# D1H register map
Vendor: Allwinner; File version: 1.0
Registers are 32-bit, read-write, reset 0x0 unless marked. A register's access mark holds for its fields unless they carry their own. Offsets are from the block's base; [hi:lo] are bit positions; {n}, {i} and the like mark numbered series.

## CIR_TX — Counsumer Infrared Transmitter
Base 0x02003000
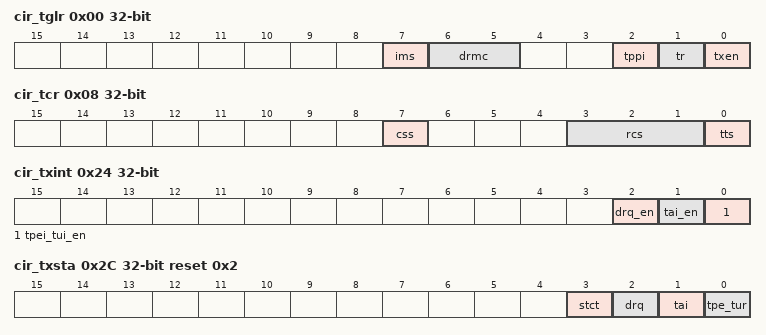
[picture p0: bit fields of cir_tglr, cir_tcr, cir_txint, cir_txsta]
0x00 cir_tglr — CIR Transmit Global Register
  [7] ims — Internal Modulation Select
    0=NOT_MODULATED (The transmitting signal is not modulated); 1=MODULATED (The transmitting signal is modulated internally)
  [6:5] drmc — Duty ratio of modulated carrier is high level/low level.
    0=EQUAL (Low level is equal to high level); 1=DOUBLE (Low level is the double of high level); 2=TRIPLE (Low level is the triple of high level)
  [2] tppi — Transmit Pulse Polarity Invert
    0=NOT_INVERT (Not invert transmit pulse); 1=INVERT (Invert transmit pulse)
  [1] tr — Transmit Reset . When this bit is set, the transmitting is reset. The FIFO will be flushed, the TIC filed and the CSS field will be cleared during Transmit Reset. This field will automatically be cleared when the Transmit Reset is finished, and the CIR transmitter will state Idle.
  [0] txen — Transmit Block Enable
    0=DISABLE (Disable the CIR Transmitter); 1=ENABLE (Enable the CIR Transmitter)
0x04 cir_tmcr reset 0x9E — CIR Transmit Modulation Control Register
  [7:0] rfmc — Reference Frequency of modulated carrier. . Reference Frequency of modulated carrier based on a division of a fixed functional clock (FCLK). The range of the modulated carrier is usually 30 kHz to 60 kHz. Most consumer electronics is 38 kHz. . The default modulated carrier is 38 kHz when FCLK is 12 MHz. . RFMC= FCLK/((N+1)*(DRMC+2)).
0x08 cir_tcr — CIR Transmit Control Register
  [7] css — Cyclical Pulse Start/Stop Control
    0=STOP (Stop when cleared to '0'. From start to stop, all data in FIFO must be transmitted.); 1=START (Start. Start to transmit when it is set to '1'.)
  [3:1] rcs — Reference Clock Select for CIR Transmit . The data in TX_FIFO is used to describe the pulse in Run-Length Code. The basic unit of pulse width is Reference Clock.
    0=IR_CLK (CIR Transmit reference clock is ir_clk); 1=IR_CLK_2 (CIR Transmit reference clock is ir_clk/2); 2=IR_CLK_4 (CIR Transmit reference clock is ir_clk/4); 3=IR_CLK_8 (CIR Transmit reference clock is ir_clk/8); 4=IR_CLK_64 (CIR Transmit reference clock is ir_clk/64); 5=IR_CLK_128 (CIR Transmit reference clock is ir_clk/128); 6=IR_CLK_256 (CIR Transmit reference clock is ir_clk/256); 7=IR_CLK_512 (CIR Transmit reference clock is ir_clk/512)
  [0] tts — Type of the transmission signal
    0=NON_CYCLICAL (The transmitting wave is a single non-cyclical pulse.); 1=CYCLICAL (The transmitting wave is a cyclical short-pulse.)
0x0C cir_idc_h — CIR Transmit Idle Duration Threshold High Bit Register
  [3:0] idc_h — Idle Duration Counter Threshold (High 4 bits) . Idle Duration = 128*IDC*Ts (IDC = 0-4095) . It is used in cyclical transmission mode. When all the data in FIFO is transmitted, the signals can be transmitted after a specific time.
0x10 cir_idc_l — CIR Transmit Idle Duration Threshold Low Bit Register
  [7:0] idc_l — Idle Duration Counter Threshold (Low 8 bits) . Idle Duration = 128*IDC*Ts (IDC = 0-4095) . It is used in cyclical transmission mode. When all the data in FIFO is transmitted, the signals can be transmitted after a specific time.
0x14 cir_ticr_h — CIR Transmit Idle Counter High Bit Register
  [7:0] tic_h ro — Transmit Idle Counter_H (High 8 bits) . It is used to count the idle duration of CIR transmitter by software. . Count in 128*Ts (Sample Duration, 1/Fs) when the transmitter is idle, and it should be reset when the transmitter is active. . When this counter reaches the maximum value (0xFFFF), it will stop automatically, and should not be cleared to zero.
0x18 cir_ticr_l — CIR Transmit Idle Counter Low Bit Register
  [7:0] tic_l ro — Transmit Idle Counter_L (Low 8 bits) . It is used to count the idle duration of CIR transmitter by software. . Count in 128*Ts (Sample Duration, 1/Fs) when the transmitter is idle, and it should be reset when the transmitter is active. . When this counter reaches the maximum value (0xFFFF), it will stop automatically, and should not be cleared to zero.
0x20 cir_tel — CIR TX FIFO Empty Level Register
  [7:0] tel — TX FIFO empty Level for DRQ and IRQ. . TRIGGER_LEVEL = TEL + 1
0x24 cir_txint — CIR Transmit Interrupt Control Register
  [all] fields
    0=DISABLE; 1=ENABLE
  [2] drq_en — TX FIFO DMA Enable . When it is set to '1', the TX FIFO DRQ is asserted if the number of the transmitting data in the FIFO is less than the RAL. The DRQ is de-asserted when the condition fails.
  [1] tai_en — TX FIFO Available Interrupt Enable
  [0] tpei_tui_en — Transmit Packet End Interrupt Enable for Cyclical Pulse / Transmitter FIFO Underrun Interrupt Enable for Non-cyclical Pulse
0x28 cir_tac reset 0x80 — CIR Transmit FIFO Available Counter Register
  [7:0] tac ro — TX FIFO Available Space Counter
    0=B0 (No available space in TX FIFO); 1=B1 (1 byte available space in TX FIFO); {v}=B{v} ({v} bytes available space in TX FIFO) (v=2..128)
0x2C cir_txsta reset 0x2 — CIR Transmit Status Register
  [3] stct ro — Status of CIR Transmitter
    0=IDLE; 1=ACTIVE
  [2] drq ro — DMA Request Flag
  [1] tai — TX FIFO Available Interrupt Flag
    0=NOT_AVAILABLE (TX FIFO not available by its level); 1=AVAILABLE (TX FIFO available by its level Writing 1 clears this bit.)
  [0] tpe_tur write-1-clears — Transmitter Packet End Flag for Cyclical Pulse / TUR Transmitter FIFO Underrun Flag for Non-cyclical Pulse
    0=NOT_COMPLETE_OR_TRANSMIT (Transmissions of address, control and data fields not completed / No transmitter FIFO underrun); 1=COMPLETE_OR_TRANSMIT (Transmissions of address, control and data fields completed / Transmitter FIFO underrun)
0x30 cir_txt — CIR Transmit Threshold Register
  [7:0] nctt — Non-cyclical Pulse Transmit Threshold . The controller will trigger transmitting the data in the FIFO when the data byte number has reached the Transmit Threshold set in this field.
0x34 cir_dma_ctl reset 0xA5 — CIR DMA Control Register
  [7:0] dma — Handshake Configuration
    165=WAITING_CYCLE (DMA waiting cycle mode); 234=HANDSHAKE (DMA handshake mode)
0x80 cir_txfifo — CIR Transmit FIFO Data Register
  [7:0] tbf wo — Transmit Byte FIFO . When the transmission is triggered, the data in the FIFO will be transmitted until the data number is transmitted completely.
